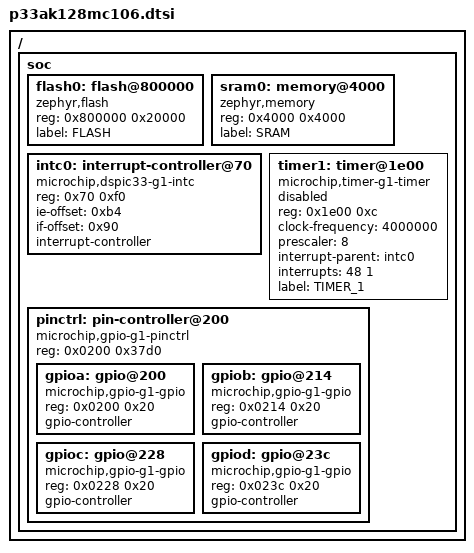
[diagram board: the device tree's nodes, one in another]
/*
 * SPDX-FileCopyrightText: Copyright (c) 2026 Microchip Technology Inc.
 * SPDX-License-Identifier: Apache-2.0
 */

#include <dspic/common/dspic33a.dtsi>

/ {
	soc: soc {
		#address-cells = <1>;
		#size-cells = <1>;

		flash0: flash@800000 {
			compatible = "zephyr,flash";
			reg = <0x800000 0x20000>;
			label = "FLASH";
		};

		sram0: memory@4000 {
			compatible = "zephyr,memory";
			reg = <0x4000 0x4000>;
			label = "SRAM";
		};

		intc0: interrupt-controller@70 {
			compatible = "microchip,dspic33-g1-intc";
			reg = <0x70 0xf0>;
			ie-offset = <0xb4>;
			if-offset = <0x90>;
			interrupt-controller;
			#address-cells = <0>;
			#interrupt-cells = <2>;
		};

		timer1: timer@1e00 {
			compatible = "microchip,timer-g1-timer";
			reg = <0x1e00 0xc>;
			clock-frequency = <4000000>;
			prescaler = <8>;
			interrupt-parent = <&intc0>;
			interrupts = <48 1>;
			label = "TIMER_1";
			status = "disabled";
		};

		pinctrl: pin-controller@200 {
			compatible = "microchip,gpio-g1-pinctrl";
			reg = <0x0200 0x37d0>;
			#address-cells = <1>;
			#size-cells = <1>;
			status = "okay";

			gpioa: gpio@200 {
				compatible = "microchip,gpio-g1-gpio";
				reg = <0x0200 0x20>;
				gpio-controller;
				#gpio-cells = <2>;
				status = "okay";
			};

			gpiob: gpio@214 {
				compatible = "microchip,gpio-g1-gpio";
				reg = <0x0214 0x20>;
				gpio-controller;
				#gpio-cells = <2>;
				status = "okay";
			};

			gpioc: gpio@228 {
				compatible = "microchip,gpio-g1-gpio";
				reg = <0x0228 0x20>;
				gpio-controller;
				#gpio-cells = <2>;
				status = "okay";
			};

			gpiod: gpio@23c {
				compatible = "microchip,gpio-g1-gpio";
				reg = <0x023c 0x20>;
				gpio-controller;
				#gpio-cells = <2>;
				status = "okay";
			};
		};
	};
};
